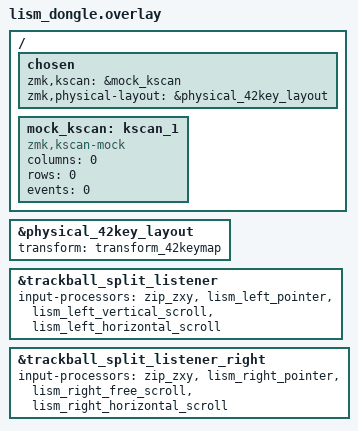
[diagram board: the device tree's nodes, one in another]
// Can't have the kscan0 here, that one's physical
/* 
    Central side is the only one that is aware of .keymap,
    so put all input processors you want to take effect in input listener here.
*/

#include "lism.dtsi"
#include "split_input.dtsi"
#include "split_input_right.dtsi"
#include "lism-layouts.dtsi"
#include <input/processors/xyz.dtsi>
#include <zephyr/dt-bindings/input/input-event-codes.h>
#include "../../../snippets/lism-dya-input-processors.dtsi"


&physical_42key_layout {
    transform = <&transform_42keymap>;
};

/* local trackball input split device child node, receiving events from the peripheral and raising them locally. */
// look into <split_input.dtsi> for mother node.
&trackball_split_listener {
    status = "okay";
    input-processors =
        <&zip_zxy
         &lism_left_pointer
         &lism_left_vertical_scroll
         &lism_left_horizontal_scroll>;
};


&trackball_split_listener_right {
    status = "okay";
    input-processors =
        <&zip_zxy
         &lism_right_pointer
         &lism_right_free_scroll
         &lism_right_horizontal_scroll>;
};


/ {
    chosen {
        zmk,kscan = &mock_kscan;
        zmk,physical-layout = &physical_42key_layout;
    };

    mock_kscan: kscan_1 {
        compatible = "zmk,kscan-mock";
        columns = <0>;
        rows = <0>;
        events = <0>;
    };
};
